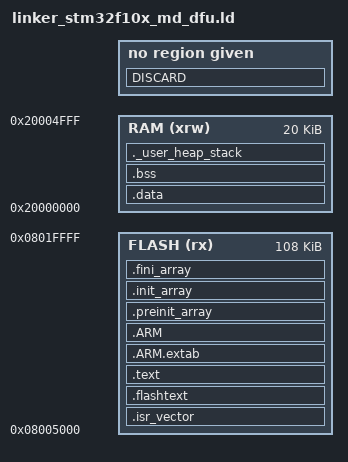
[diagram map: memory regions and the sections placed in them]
/*
*****************************************************************************
**
**  File        : linker_stm32f10x_md_dfu.ld
**
**  Abstract    : Linker script for STM32F103CB Device with
**                128KByte FLASH, 20KByte RAM
**
**                Set heap size, stack size and stack location according
**                to application requirements.
**
**                Set memory bank area and size if external memory is used.
**
**  Target      : STMicroelectronics STM32
**
**  Environment : Eclipse-CDT and GNU Tools ARM Embedded. 
**
*****************************************************************************
*/

/* Highest address of the user mode stack */
_estack = 0x20005000;

/* Generate a link error if heap and stack don't fit into RAM */
_Min_Heap_Size = 0;      /* required amount of heap  */
_Min_Stack_Size = 0x100; /* required amount of stack */

/* include the memory spaces definitions sub-script */
/*
Linker subscript for STM32F10x definitions with 128K Flash and 20K RAM */

/* Memory Spaces Definitions */

MEMORY
{
  RAM (xrw)     : ORIGIN = 0x20000000, LENGTH = 20K
  FLASH (rx)    : ORIGIN = 0x08005000, LENGTH = 128K-0x5000
}

/* include the sections management sub-script for FLASH mode */

/* Sections Definitions */

SECTIONS
{
    /* for Cortex devices, the beginning of the startup code is stored in the .isr_vector section, which goes to FLASH */
    .isr_vector :
    {
	. = ALIGN(4);
        KEEP(*(.isr_vector))            /* Startup code */
	. = ALIGN(4);
    } >FLASH
   
    .flashtext :
    {
	. = ALIGN(4);
        *(.flashtext)            /* Startup code */
	. = ALIGN(4);
    } >FLASH
     
    /* the program code is stored in the .text section, which goes to Flash */
    .text :
    {
	    . = ALIGN(4);
	    
        *(.text)                   /* remaining code */
        *(.text.*)                   /* remaining code */
        *(.rodata)                 /* read-only data (constants) */
        *(.rodata*)
        *(.glue_7)
        *(.glue_7t)

	    . = ALIGN(4);
   	  _etext = .;
    } >FLASH
 
    .ARM.extab   : { *(.ARM.extab* .gnu.linkonce.armextab.*) } >FLASH
    .ARM : {
        __exidx_start = .;
        *(.ARM.exidx*)
        __exidx_end = .;
    } >FLASH
 
    .preinit_array : {
        PROVIDE_HIDDEN (__preinit_array_start = .);
        KEEP (*(.preinit_array*))
        PROVIDE_HIDDEN (__preinit_array_end = .);
    } >FLASH

    .init_array : {
        PROVIDE_HIDDEN (__init_array_start = .);
        KEEP (*(SORT(.init_array.*)))
        KEEP (*(.init_array*))
        PROVIDE_HIDDEN (__init_array_end = .);
    } >FLASH

    .fini_array : {
        PROVIDE_HIDDEN (__fini_array_start = .);
        KEEP (*(.fini_array*))
        KEEP (*(SORT(.fini_array.*)))
        PROVIDE_HIDDEN (__fini_array_end = .);
    } >FLASH

    /* This is used by the startup to initialize .data  section */
    _sidata = .;
 
    /* This is the initialized data section
    The program executes knowing that the data is in the RAM
    but the loader puts the initial values in the FLASH (inidata).
    It is one task of the startup to copy the initial values from FLASH to RAM. */
    .data  : AT ( _sidata )
    {
	    . = ALIGN(4);
        /* This is used by the startup in order to initialize the .data secion */
        _sdata = . ;
        
        *(.data)
        *(.data.*)

	    . = ALIGN(4);
	    /* This is used by the startup in order to initialize the .data secion */
   	 _edata = . ;
    } >RAM
    
    /* This is the uninitialized data section */
    .bss :
    {
	    . = ALIGN(4);
        /* This is used by the startup in order to initialize the .bss secion */
        _sbss = .;
        
        *(.bss)
        *(.bss*)
        *(COMMON)
        
	    . = ALIGN(4);
	    /* This is used by the startup in order to initialize the .bss secion */
   	 _ebss = . ;
    } >RAM
    
    PROVIDE ( end = _ebss );
    PROVIDE ( _end = _ebss );
    
    /* User_heap_stack section, used to check that there is enough RAM left */
    ._user_heap_stack :
    {
        . = ALIGN(4);
        . = . + _Min_Heap_Size;
        . = . + _Min_Stack_Size;
        . = ALIGN(4);
    } >RAM
          
    /* after that it's only debugging information. */
    
    /* remove the debugging information from the standard libraries */
    DISCARD :
    {
     libc.a ( * )
     libm.a ( * )
     libgcc.a ( * )
     }

    /* Stabs debugging sections.  */
    .stab          0 : { *(.stab) }
    .stabstr       0 : { *(.stabstr) }
    .stab.excl     0 : { *(.stab.excl) }
    .stab.exclstr  0 : { *(.stab.exclstr) }
    .stab.index    0 : { *(.stab.index) }
    .stab.indexstr 0 : { *(.stab.indexstr) }
    .comment       0 : { *(.comment) }
    /* DWARF debug sections.
       Symbols in the DWARF debugging sections are relative to the beginning
       of the section so we begin them at 0.  */
    /* DWARF 1 */
    .debug          0 : { *(.debug) }
    .line           0 : { *(.line) }
    /* GNU DWARF 1 extensions */
    .debug_srcinfo  0 : { *(.debug_srcinfo) }
    .debug_sfnames  0 : { *(.debug_sfnames) }
    /* DWARF 1.1 and DWARF 2 */
    .debug_aranges  0 : { *(.debug_aranges) }
    .debug_pubnames 0 : { *(.debug_pubnames) }
    /* DWARF 2 */
    .debug_info     0 : { *(.debug_info .gnu.linkonce.wi.*) }
    .debug_abbrev   0 : { *(.debug_abbrev) }
    .debug_line     0 : { *(.debug_line) }
    .debug_frame    0 : { *(.debug_frame) }
    .debug_str      0 : { *(.debug_str) }
    .debug_loc      0 : { *(.debug_loc) }
    .debug_macinfo  0 : { *(.debug_macinfo) }
    /* SGI/MIPS DWARF 2 extensions */
    .debug_weaknames 0 : { *(.debug_weaknames) }
    .debug_funcnames 0 : { *(.debug_funcnames) }
    .debug_typenames 0 : { *(.debug_typenames) }
    .debug_varnames  0 : { *(.debug_varnames) }
}

